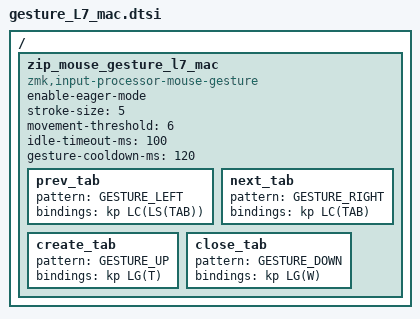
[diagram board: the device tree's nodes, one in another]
/ {
  zip_mouse_gesture_l7_mac: zip_mouse_gesture_l7_mac {
    compatible = "zmk,input-processor-mouse-gesture";
    #input-processor-cells = <0>;
    enable-eager-mode;
    stroke-size = <5>;
    movement-threshold = <6>;
    idle-timeout-ms = <100>;
    gesture-cooldown-ms = <120>;

    prev_tab   { pattern = <GESTURE_LEFT>;  bindings = <&kp LC(LS(TAB))>; };  // 前のタブ（Mac同じ）
    next_tab   { pattern = <GESTURE_RIGHT>; bindings = <&kp LC(TAB)>;     };  // 次のタブ（Mac同じ）
    create_tab { pattern = <GESTURE_UP>;    bindings = <&kp LG(T)>;       };  // 新規タブ Cmd+T
    close_tab  { pattern = <GESTURE_DOWN>;  bindings = <&kp LG(W)>;       };  // タブ閉じる Cmd+W
  };
};
